AUTOSAR XML (schema 4-0-3)
standard types defined: Boolean, UInt16, UInt32, UInt8
package /AUTOSAR_Platform/DataConstrs
  range DC_Boolean: raw 0..1
  range DC_UInt16: raw 0..65535
  range DC_UInt8: raw 0..255
package /PATAC/MSM/ComponentTypes
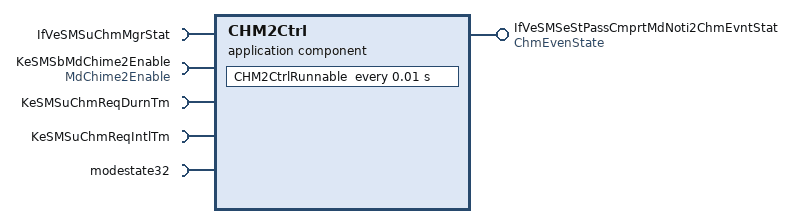
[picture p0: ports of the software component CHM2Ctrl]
  application sw component type CHM2Ctrl
    provide port IfVeSMSeStPassCmprtMdNoti2ChmEvntStat: nonqueued-sender-com-spec=data-element=ChmEvenState/Val, provided-interface=ChmEvenState
    5 x require port:
      IfVeSMSuChmMgrStat: nonqueued-receiver-com-spec{data-element=IfVeSMSuChmMgrStat/Val, filter=data-filter-type=ALWAYS}, required-interface=IfVeSMSuChmMgrStat
      KeSMSbMdChime2Enable: parameter-require-com-spec{init-value=0, parameter=MdChime2Enable/Val}, required-interface=MdChime2Enable
      KeSMSuChmReqDurnTm: parameter-require-com-spec{init-value=200, parameter=KeSMSuChmReqDurnTm/Val}, required-interface=KeSMSuChmReqDurnTm
      KeSMSuChmReqIntlTm: parameter-require-com-spec{init-value=50, parameter=KeSMSuChmReqIntlTm/Val}, required-interface=KeSMSuChmReqIntlTm
      modestate32: nonqueued-receiver-com-spec{data-element=modestate32/Val, filter=data-filter-type=ALWAYS, init-value=0}, required-interface=modestate32
    behavior CHM2Ctrl_InternalBehavior
      timing event TMT_CHM2CtrlRunnable: start-on-event=CHM2CtrlRunnable, period=0.01
      runnable CHM2CtrlRunnable
        data-receive-point-by-arguments:
          access REC_IfVeSMSuChmMgrStat_Val: accessed-variable=IfVeSMSuChmMgrStat.Val
          access REC_modestate32_Val: accessed-variable=modestate32.Val
        data-send-points:
          access SEND_IfVeSMSeStPassCmprtMdNoti2ChmEvntStat_Val: accessed-variable=IfVeSMSeStPassCmprtMdNoti2ChmEvntStat.Val
        parameter access PA_KeSMSbMdChime2Enable_Val: accessed-parameter=KeSMSbMdChime2Enable.Val
        parameter access PA_KeSMSuChmReqDurnTm_Val: accessed-parameter=KeSMSuChmReqDurnTm.Val
        parameter access PA_KeSMSuChmReqIntlTm_Val: accessed-parameter=KeSMSuChmReqIntlTm.Val
  swc implementation CHM2Ctrl_Implementation: behavior=CHM2Ctrl_InternalBehavior
    code-descriptors:
      code Default: artifact-descriptors=autosar-engineering-object={short-label=Default, category=SWSRC}
package /PATAC/MSM/ModeAdjust/CalPortInterface
  parameter interface MdChime2Enable
    parameter data prototype Val: sw-calibration-access=READ-WRITE, type=Boolean
package /PATAC/MSM/ModeAdjust/DataType
  impl type EventSts1: category=VALUE, base-type=UInt8, sw-calibration-access=READ-ONLY, compu {0=EventSts_NoAct, 1=EventSts_Act, 2=EventSts_CancleChime}, type-emitter=RTE
package /PATAC/MSM/ModeAdjust/PortInterface
  sender receiver interface ChmEvenState: invalidation-policy{data-element=ChmEvenState/Val, handle-invalid=DONT-INVALIDATE}
    data Val: type=EventSts1
  sender receiver interface IfVeSMSuChmMgrStat: invalidation-policy{data-element=IfVeSMSuChmMgrStat/Val, handle-invalid=DONT-INVALIDATE}
    data Val: type=UInt16
  sender receiver interface modestate32: invalidation-policy{data-element=modestate32/Val, handle-invalid=DONT-INVALIDATE}
    data Val: type=UInt32
package /PATAC/MSM/PortInterfaces
  parameter interface KeSMSuChmReqDurnTm
    parameter data prototype Val: sw-calibration-access=READ-WRITE, type=UInt8
  parameter interface KeSMSuChmReqIntlTm
    parameter data prototype Val: sw-calibration-access=READ-WRITE, type=UInt8
